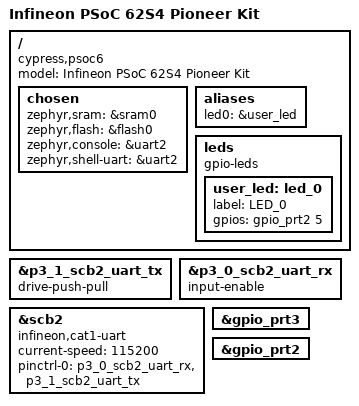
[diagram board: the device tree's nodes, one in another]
/*
 * Copyright (c) 2023 David Ullmann
 * SPDX-License-Identifier: Apache-2.0
 */

/dts-v1/;
#include <infineon/psoc6/mpns/CY8C6244LQI_S4D92.dtsi>

/ {
	model = "Infineon PSoC 62S4 Pioneer Kit";
	compatible ="cypress,psoc6";
	chosen {
		zephyr,sram = &sram0;
		zephyr,flash = &flash0;
		zephyr,console = &uart2;
		zephyr,shell-uart = &uart2;
	};

	aliases {
		led0 = &user_led;
	};

	leds {
		compatible = "gpio-leds";
		user_led: led_0 {
			label = "LED_0";
			gpios = <&gpio_prt2 5 GPIO_ACTIVE_HIGH>;
		};

	};

};

&p3_1_scb2_uart_tx {
	drive-push-pull;
};

&p3_0_scb2_uart_rx {
	input-enable;
};


uart2: &scb2 {
	compatible = "infineon,cat1-uart";
	status = "okay";
	current-speed = <115200>;
	pinctrl-0 = <&p3_0_scb2_uart_rx &p3_1_scb2_uart_tx>;
	pinctrl-names = "default";
};

&gpio_prt3 {
	status = "okay";
};

&gpio_prt2 {
	status = "okay";
};
